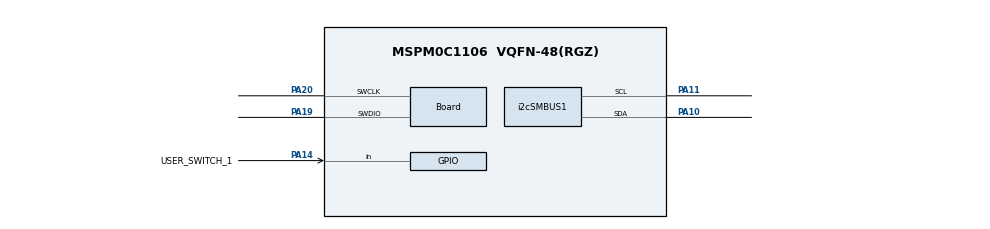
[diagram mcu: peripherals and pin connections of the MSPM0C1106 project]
//@cliArgs --device "MSPM0C1105_C1106" --package "VQFN-48(RGZ)" --part "Default"
//@v2CliArgs --device "MSPM0C1106" --package "VQFN-48(RGZ)"
// @cliArgs --board /ti/boards/LP_MSPM0C1106 --rtos nortos

/**
 * Import the modules used in this configuration.
 */
const Board         = scripting.addModule("/ti/driverlib/Board");
const GPIO          = scripting.addModule("/ti/driverlib/GPIO", {}, false);
const GPIO1         = GPIO.addInstance();
const GPIO2         = GPIO.addInstance();
const i2cSMBUS      = scripting.addModule("/ti/driverlib/i2cSMBUS", {}, false);
const i2cSMBUS1     = i2cSMBUS.addInstance();
const ProjectConfig = scripting.addModule("/ti/project_config/ProjectConfig");

/**
 * Write custom configuration values to the imported modules.
 */
Board.peripheral.$assign          = "DEBUGSS";
Board.peripheral.swclkPin.$assign = "PA20";
Board.peripheral.swdioPin.$assign = "PA19";

GPIO1.$name                   = "SMB_GPIO";
GPIO1.associatedPins.create(2);
GPIO1.associatedPins[0].$name = "LED_DEMO";
GPIO1.associatedPins[1].$name = "LED_ERROR";

GPIO2.$name                              = "GPIO_SWITCHES";
GPIO2.associatedPins[0].$name            = "USER_SWITCH_1";
GPIO2.associatedPins[0].direction        = "INPUT";
GPIO2.associatedPins[0].internalResistor = "PULL_UP";
GPIO2.associatedPins[0].interruptEn      = true;
GPIO2.associatedPins[0].polarity         = "FALL";
GPIO2.associatedPins[0].pin.$assign      = "PA14";

const SYSCTL              = scripting.addModule("/ti/driverlib/SYSCTL", {}, false);
SYSCTL.peripheral.$assign = "SYSCTL";

i2cSMBUS1.$name                             = "SMB_I2C";
i2cSMBUS1.enableTimeoutA                    = true;
i2cSMBUS1.intGeneric                        = ["TIMEOUT_A"];
i2cSMBUS1.basicEnableTarget                 = true;
i2cSMBUS1.advTargetTXEmptyEn                = true;
i2cSMBUS1.basicTargetAddress                = 0x43;
i2cSMBUS1.advTargetAckOverride              = true;
i2cSMBUS1.enableTargetPECACKNext            = true;
i2cSMBUS1.enableTargetPEC                   = true;
i2cSMBUS1.intTarget                         = ["RXFIFO_TRIGGER","START","STOP","TXFIFO_EMPTY"];
i2cSMBUS1.timeoutACount                     = 135;
i2cSMBUS1.basicEnableController             = true;
i2cSMBUS1.intController                     = ["ARBITRATION_LOST","NACK","RXFIFO_TRIGGER","STOP"];
i2cSMBUS1.peripheral.$assign                = "I2C0";
i2cSMBUS1.peripheral.sdaPin.$assign         = "PA10";
i2cSMBUS1.peripheral.sclPin.$assign         = "PA11";

ProjectConfig.genLibSMBUS        = true;
ProjectConfig.migrationCondition = true;
